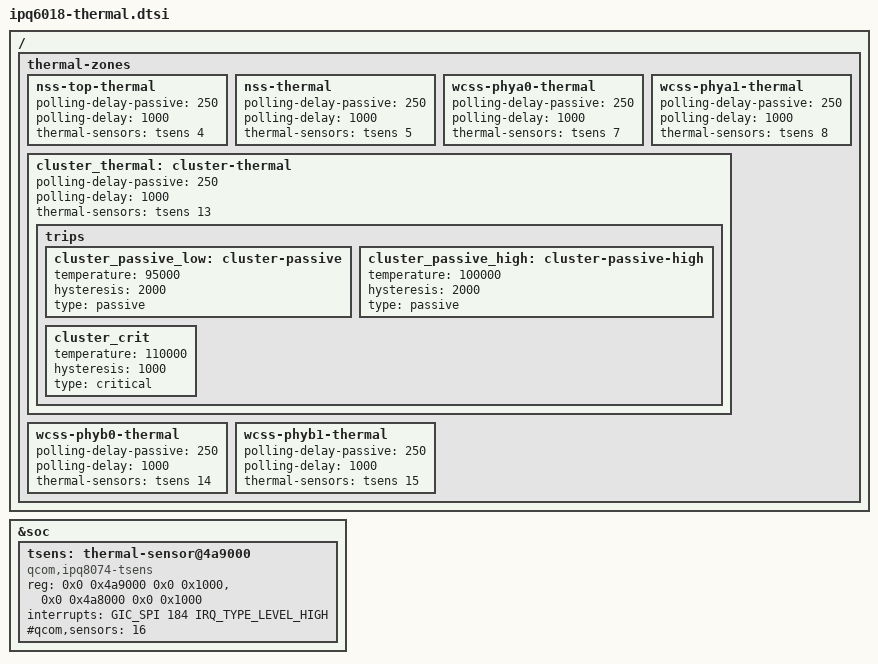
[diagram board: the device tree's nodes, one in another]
/*
 * Copyright (c) 2019-2020, The Linux Foundation. All rights reserved.
 *
 * Permission to use, copy, modify, and/or distribute this software for any
 * purpose with or without fee is hereby granted, provided that the above
 * copyright notice and this permission notice appear in all copies.
 *
 * THE SOFTWARE IS PROVIDED "AS IS" AND THE AUTHOR DISCLAIMS ALL WARRANTIES
 * WITH REGARD TO THIS SOFTWARE INCLUDING ALL IMPLIED WARRANTIES OF
 * MERCHANTABILITY AND FITNESS. IN NO EVENT SHALL THE AUTHOR BE LIABLE FOR
 * ANY SPECIAL, DIRECT, INDIRECT, OR CONSEQUENTIAL DAMAGES OR ANY DAMAGES
 * WHATSOEVER RESULTING FROM LOSS OF USE, DATA OR PROFITS, WHETHER IN AN
 * ACTION OF CONTRACT, NEGLIGENCE OR OTHER TORTIOUS ACTION, ARISING OUT OF
 * OR IN CONNECTION WITH THE USE OR PERFORMANCE OF THIS SOFTWARE.
 */
 #include <dt-bindings/thermal/thermal.h>

/ {
	thermal-zones {
		nss-top-thermal {
			polling-delay-passive = <250>;
			polling-delay = <1000>;

			thermal-sensors = <&tsens 4>;
		};

		nss-thermal {
			polling-delay-passive = <250>;
			polling-delay = <1000>;

			thermal-sensors = <&tsens 5>;
		};

		wcss-phya0-thermal {
			polling-delay-passive = <250>;
			polling-delay = <1000>;

			thermal-sensors = <&tsens 7>;
		};

		wcss-phya1-thermal {
			polling-delay-passive = <250>;
			polling-delay = <1000>;

			thermal-sensors = <&tsens 8>;
		};

		cluster_thermal: cluster-thermal {
			polling-delay-passive = <250>;
			polling-delay = <1000>;

			thermal-sensors = <&tsens 13>;

			trips {
				cluster_passive_low: cluster-passive {
					temperature = <95000>;
					hysteresis = <2000>;
					type = "passive";
				};

				cluster_passive_high: cluster-passive-high {
					temperature = <100000>;
					hysteresis = <2000>;
					type = "passive";
				};

				cluster_crit: cluster_crit {
					temperature = <110000>;
					hysteresis = <1000>;
					type = "critical";
				};
			};
		};

		wcss-phyb0-thermal {
			polling-delay-passive = <250>;
			polling-delay = <1000>;

			thermal-sensors = <&tsens 14>;
		};

		wcss-phyb1-thermal {
			polling-delay-passive = <250>;
			polling-delay = <1000>;

			thermal-sensors = <&tsens 15>;
		};
	};
};



&soc {
	tsens: thermal-sensor@4a9000 {
			compatible = "qcom,ipq8074-tsens";
			reg = <0x0 0x4a9000 0x0 0x1000>, /* TM */
			      <0x0 0x4a8000 0x0 0x1000>; /* SROT */
			interrupts = <GIC_SPI 184 IRQ_TYPE_LEVEL_HIGH>;
			interrupt-names = "combined";
			#qcom,sensors = <16>;
			#thermal-sensor-cells = <1>;
	};
};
